# MKW01Z4 register map
File version: 1.6
Registers are 32-bit, read-write, reset 0x0 unless marked. A register's access mark holds for its fields unless they carry their own. Offsets are from the block's base; [hi:lo] are bit positions; {n}, {i} and the like mark numbered series; 'fields as' and 'values as' point back to an identical list.

## CMP0 — High-Speed Comparator (CMP), Voltage Reference (VREF) Digital-to-Analog Converter (DAC), and Analog Mux (ANMUX)
Base 0x40073000; register names take the prefix CMP0_
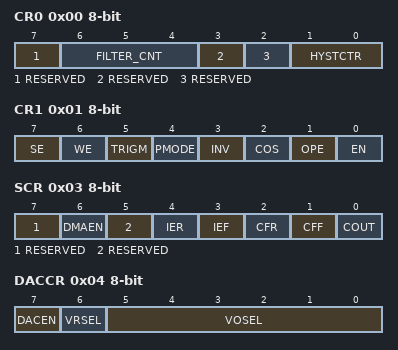
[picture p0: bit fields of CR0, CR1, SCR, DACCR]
0x00 CR0 8-bit — CMP Control Register 0
  [7] RESERVED ro
  [6:4] FILTER_CNT — Filter Sample Count
    0=Filter is disabled. If SE = 1, then COUT is a logic 0. This is not a legal state, and is not recommended. If SE = 0, COUT = COUTA.; 1=One sample must agree. The comparator output is simply sampled.; {v}={v} consecutive samples must agree (v=2..7)
  [3] RESERVED ro
  [2] RESERVED ro
  [1:0] HYSTCTR — Comparator hard block hysteresis control
    {v}=Level {v} (v=0..3)
0x01 CR1 8-bit — CMP Control Register 1
  [7] SE — Sample Enable
    0=Sampling mode is not selected; 1=Sampling mode is selected
  [6] WE — Windowing Enable
    0=Windowing mode is not selected; 1=Windowing mode is selected
  [5] TRIGM — Trigger Mode Enable
    0=Trigger mode is disabled; 1=Trigger mode is enabled
  [4] PMODE — Power Mode Select
    0=Low-Speed (LS) Comparison mode selected. In this mode, CMP has slower output propagation delay and lower current consumption.; 1=High-Speed (HS) Comparison mode selected. In this mode, CMP has faster output propagation delay and higher current consumption.
  [3] INV — Comparator INVERT
    0=Does not invert the comparator output; 1=Inverts the comparator output
  [2] COS — Comparator Output Select
    0=Set the filtered comparator output (CMPO) to equal COUT; 1=Set the unfiltered comparator output (CMPO) to equal COUTA
  [1] OPE — Comparator Output Pin Enable
    0=CMPO is not available on the associated CMPO output pin. If the comparator does not own the pin, this field has no effect.; 1=CMPO is available on the associated CMPO output pin. The comparator output (CMPO) is driven out on the associated CMPO output pin if the comparator owns the pin. If the comparator does not own the field, this bit has no effect.
  [0] EN — Comparator Module Enable
    0=Analog Comparator is disabled; 1=Analog Comparator is enabled
0x02 FPR 8-bit — CMP Filter Period Register
  [7:0] FILT_PER — Filter Sample Period
0x03 SCR 8-bit — CMP Status and Control Register
  [7] RESERVED ro
  [6] DMAEN — DMA Enable Control
    0=DMA is disabled; 1=DMA is enabled
  [5] RESERVED ro
  [4] IER — Comparator Interrupt Enable Rising
    0=Interrupt is disabled; 1=Interrupt is enabled
  [3] IEF — Comparator Interrupt Enable Falling
    0=Interrupt is disabled; 1=Interrupt is enabled
  [2] CFR — Analog Comparator Flag Rising
    0=Rising-edge on COUT has not been detected; 1=Rising-edge on COUT has occurred
  [1] CFF — Analog Comparator Flag Falling
    0=Falling-edge on COUT has not been detected; 1=Falling-edge on COUT has occurred
  [0] COUT ro — Analog Comparator Output
0x04 DACCR 8-bit — DAC Control Register
  [7] DACEN — DAC Enable
    0=DAC is disabled; 1=DAC is enabled
  [6] VRSEL — Supply Voltage Reference Source Select
    0=V is selected as resistor ladder network supply reference V. in1 in; 1=V is selected as resistor ladder network supply reference V. in2 in
  [5:0] VOSEL — DAC Output Voltage Select
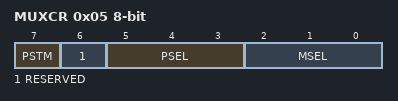
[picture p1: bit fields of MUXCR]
0x05 MUXCR 8-bit — MUX Control Register
  [7] PSTM — Pass Through Mode Enable
    0=Pass Through Mode is disabled; 1=Pass Through Mode is enabled
  [6] RESERVED ro
  [5:3] PSEL — Plus Input Mux Control
    {v}=IN{v} (v=0..7)
  [2:0] MSEL — Minus Input Mux Control
    {v}=IN{v} (v=0..7)

## LLWU — Low leakage wakeup unit
Base 0x4007C000; register names take the prefix LLWU_
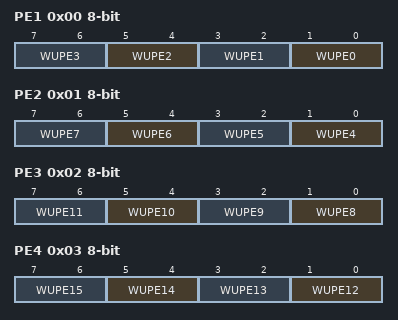
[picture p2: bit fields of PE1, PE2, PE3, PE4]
0x00 PE1 8-bit — LLWU Pin Enable 1 register
  [all] fields
    0=External input pin disabled as wakeup input; 1=External input pin enabled with rising edge detection; 2=External input pin enabled with falling edge detection; 3=External input pin enabled with any change detection
  [2n+1:2n] WUPE{n} (n=0..3) — Wakeup Pin Enable For LLWU_P{n}
0x01 PE2 8-bit — LLWU Pin Enable 2 register
  [all] fields
    values as the fields of PE1
  [2n-7:2n-8] WUPE{n} (n=4..7) — Wakeup Pin Enable For LLWU_P{n}
0x02 PE3 8-bit — LLWU Pin Enable 3 register
  [all] fields
    values as the fields of PE1
  [2n-15:2n-16] WUPE{n} (n=8..11) — Wakeup Pin Enable For LLWU_P{n}
0x03 PE4 8-bit — LLWU Pin Enable 4 register
  [all] fields
    values as the fields of PE1
  [2n-23:2n-24] WUPE{n} (n=12..15) — Wakeup Pin Enable For LLWU_P{n}
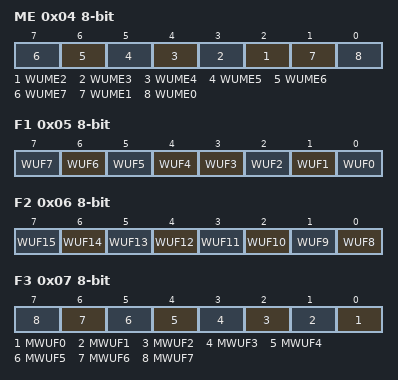
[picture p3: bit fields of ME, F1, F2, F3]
0x04 ME 8-bit — LLWU Module Enable register
  [all] fields
    0=Internal module flag not used as wakeup source; 1=Internal module flag used as wakeup source
  [n] WUME{n} (n=2..7) — Wakeup Module Enable For Module {n}
  [1] WUME1 — Wakeup Module Enable for Module 1
  [0] WUME0 — Wakeup Module Enable For Module 0
0x05 F1 8-bit — LLWU Flag 1 register
  [n] WUF{n} (n=4..7) — Wakeup Flag For LLWU_P{n}
    0=LLWU_P{n} input was not a wakeup source; 1=LLWU_P{n} input was a wakeup source
  [3] WUF3 — Wakeup Flag For LLWU_P3
    0=LLWU_P3 input was not a wake-up source; 1=LLWU_P3 input was a wake-up source
  [2] WUF2 — Wakeup Flag For LLWU_P2
    0=LLWU_P2 input was not a wakeup source; 1=LLWU_P2 input was a wakeup source
  [1] WUF1 — Wakeup Flag For LLWU_P1
    0=LLWU_P1 input was not a wakeup source; 1=LLWU_P1 input was a wakeup source
  [0] WUF0 — Wakeup Flag For LLWU_P0
    0=LLWU_P0 input was not a wakeup source; 1=LLWU_P0 input was a wakeup source
0x06 F2 8-bit — LLWU Flag 2 register
  [n-8] WUF{n} (n=8..15) — Wakeup Flag For LLWU_P{n}
    values as F1.WUF4
0x07 F3 8-bit ro — LLWU Flag 3 register
  [n] MWUF{n} (n=0..7) — Wakeup flag For module {n}
    0=Module {n} input was not a wakeup source; 1=Module {n} input was a wakeup source
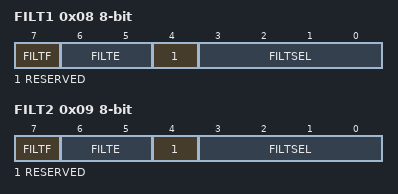
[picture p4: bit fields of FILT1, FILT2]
0x08 FILT1 8-bit — LLWU Pin Filter 1 register
  [7] FILTF — Filter Detect Flag
    0=Pin Filter 1 was not a wakeup source; 1=Pin Filter 1 was a wakeup source
  [6:5] FILTE — Digital Filter On External Pin
    0=Filter disabled; 1=Filter posedge detect enabled; 2=Filter negedge detect enabled; 3=Filter any edge detect enabled
  [4] RESERVED ro
  [3:0] FILTSEL — Filter Pin Select
    0=Select LLWU_P0 for filter; 15=Select LLWU_P15 for filter
0x09 FILT2 8-bit — LLWU Pin Filter 2 register
  [7] FILTF — Filter Detect Flag
    0=Pin Filter 2 was not a wakeup source; 1=Pin Filter 2 was a wakeup source
  [6:5] FILTE — Digital Filter On External Pin
    values as FILT1.FILTE
  [4] RESERVED ro
  [3:0] FILTSEL — Filter Pin Select
    0=Select LLWU_P0 for filter; 15=Select LLWU_P15 for filter
